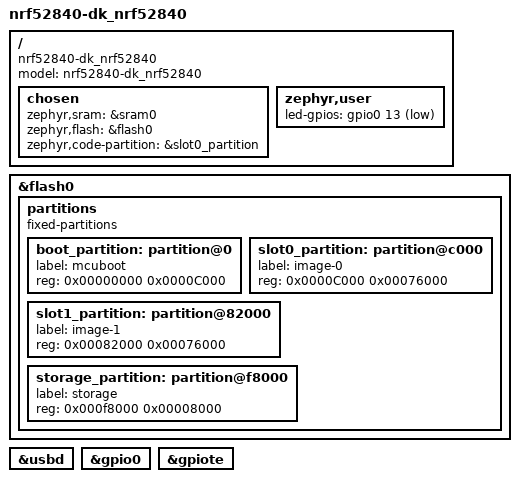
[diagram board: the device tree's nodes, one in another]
// Copyright (c) 2024 Nordic Semiconductor ASA
// SPDX-License-Identifier: Apache-2.0

/dts-v1/;
#include <nordic/nrf52840_qiaa.dtsi>

/ {
	model = "nrf52840-dk_nrf52840";
	compatible = "nrf52840-dk_nrf52840";

	chosen {
		zephyr,sram = &sram0;
		zephyr,flash = &flash0;
		zephyr,code-partition = &slot0_partition;
	};

	zephyr,user {
		led-gpios = <&gpio0 13 (GPIO_ACTIVE_LOW | GPIO_OPEN_DRAIN)>;
	};
};

&flash0 {
	partitions {
		compatible = "fixed-partitions";
		#address-cells = <1>;
		#size-cells = <1>;

		// use original partitioning to keep nvs
		boot_partition: partition@0 {
			label = "mcuboot";
			reg = <0x00000000 0x0000C000>;
		};
		slot0_partition: partition@c000 {
			label = "image-0";
			reg = <0x0000C000 0x00076000>;
		};
		slot1_partition: partition@82000 {
			label = "image-1";
			reg = <0x00082000 0x00076000>;
		};
		storage_partition: partition@f8000 {
			label = "storage";
			reg = <0x000f8000 0x00008000>;
		};
	};
};

&usbd {
	status = "okay";
};

&gpio0 {
	status = "okay";
};

&gpiote {
	status = "okay";
};
